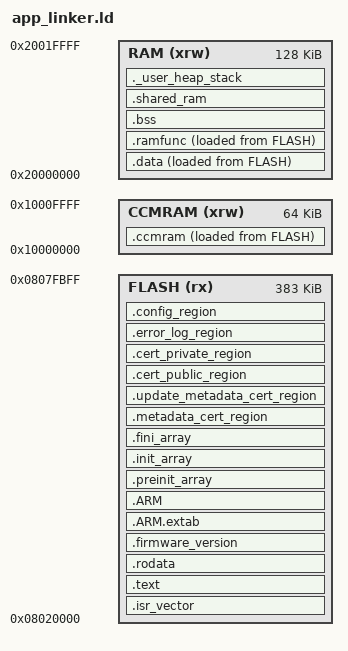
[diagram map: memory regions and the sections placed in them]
/*
******************************************************************************
**
** @file        : LinkerScript.ld
**
** @author      : Auto-generated by STM32 VS Code Extension
**
**  Abstract    : Linker script for STM32F407G-DISC1 Board embedding STM32F407VGTx Device from stm32f4 series
**                      1024Kbytes FLASH
**                      64Kbytes CCMRAM
**                      128Kbytes RAM
**
**                Set heap size, stack size and stack location according
**                to application requirements.
**
**                Set memory bank area and size if external memory is used
**
**  Target      : STMicroelectronics STM32
**
**  Distribution: The file is distributed as is, without any warranty
**                of any kind.
**
******************************************************************************
** @attention
**
** Copyright (c) 2025 STMicroelectronics.
** All rights reserved.
**
** This software is licensed under terms that can be found in the LICENSE file
** in the root directory of this software component.
** If no LICENSE file comes with this software, it is provided AS-IS.
**
******************************************************************************
*/

/* Entry Point */
ENTRY(Reset_Handler)

/* Stack and heap configuration */
_estack = ORIGIN(RAM) + LENGTH(RAM);
_Min_Heap_Size = 0x200;
_Min_Stack_Size = 0x400;

/* Memory layout */
MEMORY
{
  CCMRAM (xrw): ORIGIN = 0x10000000, LENGTH = 64K
  RAM    (xrw): ORIGIN = 0x20000000, LENGTH = 128K
  FLASH  (rx) : ORIGIN = 0x08020000, LENGTH = 384K - 1K
}

/* Place metadata and cert manually */
__app_end = ORIGIN(FLASH) + LENGTH(FLASH);

/* Sections */
SECTIONS
{
  /* The startup code into "FLASH" Rom type memory */
  .isr_vector :
  {
    . = ALIGN(4);
    KEEP(*(.isr_vector)) /* Startup code */
    . = ALIGN(4);
  } >FLASH

  /* The program code and other data into "FLASH" Rom type memory */
  .text :
  {
    . = ALIGN(4);
    *(.text)           /* .text sections (code) */
    *(.text*)          /* .text* sections (code) */
    *(.glue_7)         /* glue arm to thumb code */
    *(.glue_7t)        /* glue thumb to arm code */
    *(.eh_frame)

    KEEP (*(.init))
    KEEP (*(.fini))

    . = ALIGN(4);
    _etext = .;        /* define a global symbols at end of code */
  } >FLASH

  /* Constant data into "FLASH" Rom type memory */
  .rodata :
  {
    . = ALIGN(4);
    *(.rodata)         /* .rodata sections (constants, strings, etc.) */
    *(.rodata*)        /* .rodata* sections (constants, strings, etc.) */
    . = ALIGN(4);
  } >FLASH

  /* Firmware version section into "FLASH" Rom type memory */
  .firmware_version :
  {
    . = ALIGN(4);
    KEEP(*(.firmware_version))
    . = ALIGN(4);
  } >FLASH

  .ARM.extab :
  {
    . = ALIGN(4);
    *(.ARM.extab* .gnu.linkonce.armextab.*)
    . = ALIGN(4);
  } >FLASH

  .ARM :
  {
    . = ALIGN(4);
    __exidx_start = .;
    *(.ARM.exidx*)
    __exidx_end = .;
    . = ALIGN(4);
  } >FLASH

  .preinit_array :
  {
    . = ALIGN(4);
    PROVIDE_HIDDEN(__preinit_array_start = .);
    KEEP(*(.preinit_array*))
    PROVIDE_HIDDEN(__preinit_array_end = .);
    . = ALIGN(4);
  } >FLASH

  .init_array :
  {
    . = ALIGN(4);
    PROVIDE_HIDDEN(__init_array_start = .);
    KEEP(*(SORT(.init_array.*)))
    KEEP(*(.init_array*))
    PROVIDE_HIDDEN(__init_array_end = .);
    . = ALIGN(4);
  } >FLASH

  .fini_array :
  {
    . = ALIGN(4);
    PROVIDE_HIDDEN(__fini_array_start = .);
    KEEP(*(SORT(.fini_array.*)))
    KEEP(*(.fini_array*))
    PROVIDE_HIDDEN(__fini_array_end = .);
    . = ALIGN(4);
  } >FLASH

  _sidata = LOADADDR(.data);

  /* Initialized data sections into "RAM" Ram type memory */
  .data :
  {
    . = ALIGN(4);
    _sdata = .;        /* create a global symbol at data start */
    *(.data)           /* .data sections */
    *(.data*)          /* .data* sections */
    *(.RamFunc)        /* .RamFunc sections */
    *(.RamFunc*)       /* .RamFunc* sections */

    . = ALIGN(4);
    _edata = .;        /* define a global symbol at data end */

  } >RAM AT> FLASH

  _siccmram = LOADADDR(.ccmram);

  /* CCM-RAM section
  *
  * IMPORTANT NOTE!
  * If initialized variables will be placed in this section,
  * the startup code needs to be modified to copy the init-values.
  */
  .ccmram :
  {
    . = ALIGN(4);
    _sccmram = .;       /* create a global symbol at ccmram start */
    *(.ccmram)
    *(.ccmram*)
    . = ALIGN(4);
    _eccmram = .;       /* create a global symbol at ccmram end */
  } >CCMRAM AT> FLASH

  /* RAM-executed flash functions */
  .ramfunc :
  {
    . = ALIGN(4);
    _sramfunc = .;
    KEEP(*(.ramfunc))
    KEEP(*(.ramfunc*))
    . = ALIGN(4);
    _eramfunc = .;
  } >RAM AT> FLASH

  _sidata_ramfunc = LOADADDR(.ramfunc);

  /* Uninitialized data section into "RAM" Ram type memory */
  . = ALIGN(4);
  .bss :
  {
    /* This is used by the startup in order to initialize the .bss section */
    _sbss = .;         /* define a global symbol at bss start */
    __bss_start__ = _sbss;
    *(.bss)
    *(.bss*)
    *(COMMON)
    . = ALIGN(4);
    _ebss = .;         /* define a global symbol at bss end */
    __bss_end__ = _ebss;
  } >RAM

  /* Shared RAM section for bootloader - app communication */
  .shared_ram (NOLOAD) :
  {
    . = ALIGN(4);
    KEEP(*(.shared_ram))
    . = ALIGN(4);
  } >RAM

  /* User_heap_stack section, used to check that there is enough "RAM" Ram  type memory left */
  ._user_heap_stack :
  {
    . = ALIGN(8);
    PROVIDE(end = .);
    PROVIDE(_end = .);
    . = . + _Min_Heap_Size;
    . = . + _Min_Stack_Size;
    . = ALIGN(8);
  } >RAM

  /* Optional: Update region metadata + cert */
  .metadata_cert_region (NOLOAD) :
  {
    __metadata_start__ = 0x0807FC00;
    __cert_start__     = 0x0807FE00;
  } >FLASH

  .update_metadata_cert_region (NOLOAD) :
  {
    __new_metadata_start__ = 0x080FFC00;
    __new_cert_start__     = 0x080FFE00;
  } >FLASH

  .cert_public_region (NOLOAD) :
  {
    __cert_public_start__ = 0x080F8400;
  } >FLASH

  .cert_private_region (NOLOAD) :
  {
    __cert_private_start__ = 0x08004000;
  } >FLASH

  .error_log_region (NOLOAD) :
  {
    __error_log_start__ = 0x08008000;
  } >FLASH

  .config_region (NOLOAD) :
  {
    __config_start__ = 0x0800C000;
  } >FLASH

  /* Remove information from the compiler libraries */
  /DISCARD/ :
  {
    libc.a ( * )
    libm.a ( * )
    libgcc.a ( * )
  }

  .ARM.attributes 0 : { *(.ARM.attributes) }
}
